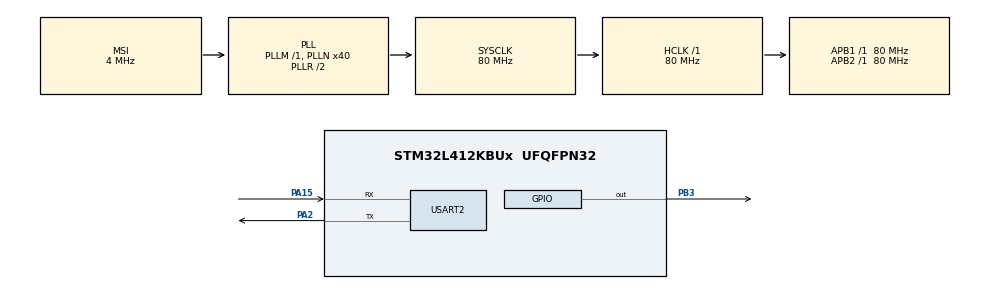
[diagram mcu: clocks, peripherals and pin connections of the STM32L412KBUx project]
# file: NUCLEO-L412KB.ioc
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Mcu.Family=STM32L4
Mcu.Name=STM32L412KBUx
Mcu.Package=UFQFPN32
NVIC.PriorityGroup=NVIC_PRIORITYGROUP_4
NVIC.TIM1_UP_TIM16_IRQn=true\:15\:0\:false\:false\:true\:false\:true\:true
NVIC.TimeBase=TIM1_UP_TIM16_IRQn
NVIC.TimeBaseIP=TIM16
PA15\ (JTDI).Mode=Asynchronous
PA15\ (JTDI).Signal=USART2_RX
PA2.Mode=Asynchronous
PA2.Signal=USART2_TX
PB3\ (JTDO/TRACESWO).Signal=GPIO_Output
ProjectManager.HeapSize=0x200
ProjectManager.StackSize=0x400
ProjectManager.TargetToolchain=STM32CubeIDE
RCC.ADCFreq_Value=80000000
RCC.AHBFreq_Value=80000000
RCC.APB1Freq_Value=80000000
RCC.APB1TimFreq_Value=80000000
RCC.APB2Freq_Value=80000000
RCC.APB2TimFreq_Value=80000000
RCC.CortexFreq_Value=80000000
RCC.HCLKFreq_Value=80000000
RCC.HSE_VALUE=8000000
RCC.HSI48_VALUE=48000000
RCC.HSI_VALUE=16000000
RCC.LSE_VALUE=32768
RCC.MSI_VALUE=4000000
RCC.PLLN=40
RCC.SYSCLKFreq_VALUE=80000000
RCC.SYSCLKSource=RCC_SYSCLKSOURCE_PLLCLK
RCC.USBFreq_Value=4000000
RCC.VCOOutputFreq_Value=160000000
USART2.VirtualMode-Asynchronous=VM_ASYNC
VP_SYS_VS_tim16.Mode=TIM16
board=custom

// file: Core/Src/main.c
/* USER CODE BEGIN Header */
/**
  ******************************************************************************
  * @file           : main.c
  * @brief          : Main program body
  ******************************************************************************
  * @attention
  *
  * Copyright (c) 2022 STMicroelectronics.
  * All rights reserved.
  *
  * This software is licensed under terms that can be found in the LICENSE file
  * in the root directory of this software component.
  * If no LICENSE file comes with this software, it is provided AS-IS.
  *
  ******************************************************************************
  */
/* USER CODE END Header */
#include "main.h"
#include "usart.h"
#include "gpio.h"

/* USER CODE BEGIN Includes */
#include "FreeRTOS.h"
#include "semphr.h"
/* USER CODE END Includes */

void SystemClock_Config(void);
/* USER CODE BEGIN PFP */
void Task1(void * params){
	while(1){
		HAL_GPIO_TogglePin(GPIOB, GPIO_PIN_3);
		SEGGER_SYSVIEW_PrintfHost("BLINK LED\r\n");
		vTaskDelay(100);
	}
}
/* USER CODE END PFP */

int main(void)
{

  /* MCU Configuration--------------------------------------------------------*/

  /* Reset of all peripherals, Initializes the Flash interface and the Systick. */
  HAL_Init();

  /* Configure the system clock */
  SystemClock_Config();

  /* Initialize all configured peripherals */
  MX_GPIO_Init();
  MX_USART2_UART_Init();
  /* USER CODE BEGIN 2 */
  DWT->CTRL |= 1;
  SEGGER_SYSVIEW_Conf();

  xTaskCreate(Task1, "tarea", configMINIMAL_STACK_SIZE, NULL, 1, NULL);

  vTaskStartScheduler();

  /* USER CODE END 2 */

  /* Infinite loop */
  while (1)
  {

  }
}

void SystemClock_Config(void)
{
  RCC_OscInitTypeDef RCC_OscInitStruct = {0};
  RCC_ClkInitTypeDef RCC_ClkInitStruct = {0};

  /** Configure the main internal regulator output voltage
  */
  if (HAL_PWREx_ControlVoltageScaling(PWR_REGULATOR_VOLTAGE_SCALE1) != HAL_OK)
  {
    Error_Handler();
  }

  /** Initializes the RCC Oscillators according to the specified parameters
  * in the RCC_OscInitTypeDef structure.
  */
  RCC_OscInitStruct.OscillatorType = RCC_OSCILLATORTYPE_MSI;
  RCC_OscInitStruct.MSIState = RCC_MSI_ON;
  RCC_OscInitStruct.MSICalibrationValue = 0;
  RCC_OscInitStruct.MSIClockRange = RCC_MSIRANGE_6;
  RCC_OscInitStruct.PLL.PLLState = RCC_PLL_ON;
  RCC_OscInitStruct.PLL.PLLSource = RCC_PLLSOURCE_MSI;
  RCC_OscInitStruct.PLL.PLLM = 1;
  RCC_OscInitStruct.PLL.PLLN = 40;
  RCC_OscInitStruct.PLL.PLLQ = RCC_PLLQ_DIV2;
  RCC_OscInitStruct.PLL.PLLR = RCC_PLLR_DIV2;
  if (HAL_RCC_OscConfig(&RCC_OscInitStruct) != HAL_OK)
  {
    Error_Handler();
  }

  /** Initializes the CPU, AHB and APB buses clocks
  */
  RCC_ClkInitStruct.ClockType = RCC_CLOCKTYPE_HCLK|RCC_CLOCKTYPE_SYSCLK
                              |RCC_CLOCKTYPE_PCLK1|RCC_CLOCKTYPE_PCLK2;
  RCC_ClkInitStruct.SYSCLKSource = RCC_SYSCLKSOURCE_PLLCLK;
  RCC_ClkInitStruct.AHBCLKDivider = RCC_SYSCLK_DIV1;
  RCC_ClkInitStruct.APB1CLKDivider = RCC_HCLK_DIV1;
  RCC_ClkInitStruct.APB2CLKDivider = RCC_HCLK_DIV1;

  if (HAL_RCC_ClockConfig(&RCC_ClkInitStruct, FLASH_LATENCY_4) != HAL_OK)
  {
    Error_Handler();
  }
}

void HAL_TIM_PeriodElapsedCallback(TIM_HandleTypeDef *htim)
{
  if (htim->Instance == TIM16) {
    HAL_IncTick();
  }
}

void Error_Handler(void)
{
  __disable_irq();
  while (1)
  {
  }
}
